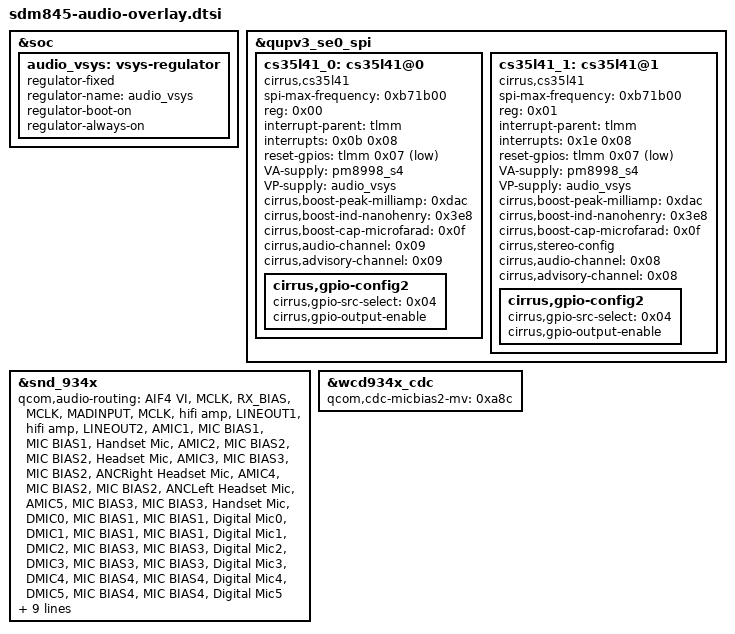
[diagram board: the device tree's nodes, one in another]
/*
 * Copyright (C) 2023 transaero21 <transaero21@elseboot.ru>
 *
 * SPDX-License-Identifier: GPL-2.0
 */

#include "../sdm845-audio-overlay.dtsi"

&soc {
	audio_vsys: vsys-regulator {
		compatible = "regulator-fixed";
		regulator-name = "audio_vsys";
		regulator-boot-on;
		regulator-always-on;
	};
};

&qupv3_se0_spi {
	cs35l41_0: cs35l41@0 {
		#sound-dai-cells = <0x01>;
		compatible = "cirrus,cs35l41";
		spi-max-frequency = <0xb71b00>;
		reg = <0x00>;
		interrupt-parent = <&tlmm>;
		interrupts = <0x0b 0x08>;
		reset-gpios = <&tlmm 0x07 0x01>;
		VA-supply = <&pm8998_s4>;
		VP-supply = <&audio_vsys>;
		cirrus,boost-peak-milliamp = <0xdac>;
		cirrus,boost-ind-nanohenry = <0x3e8>;
		cirrus,boost-cap-microfarad = <0x0f>;
		cirrus,audio-channel = <0x09>;
		cirrus,advisory-channel = <0x09>;

		cirrus,gpio-config2 {
			cirrus,gpio-src-select = <0x04>;
			cirrus,gpio-output-enable;
		};
	};
};

&qupv3_se0_spi {
	cs35l41_1: cs35l41@1 {
		#sound-dai-cells = <0x01>;
		compatible = "cirrus,cs35l41";
		spi-max-frequency = <0xb71b00>;
		reg = <0x01>;
		interrupt-parent = <&tlmm>;
		interrupts = <0x1e 0x08>;
		reset-gpios = <&tlmm 0x07 0x01>;
		VA-supply = <&pm8998_s4>;
		VP-supply = <&audio_vsys>;
		cirrus,boost-peak-milliamp = <0xdac>;
		cirrus,boost-ind-nanohenry = <0x3e8>;
		cirrus,boost-cap-microfarad = <0x0f>;
		cirrus,stereo-config;
		cirrus,audio-channel = <0x08>;
		cirrus,advisory-channel = <0x08>;

		cirrus,gpio-config2 {
			cirrus,gpio-src-select = <0x04>;
			cirrus,gpio-output-enable;
		};
	};
};

&snd_934x {
	qcom,audio-routing =
		"AIF4 VI", "MCLK",
		"RX_BIAS", "MCLK",
		"MADINPUT", "MCLK",
		"hifi amp", "LINEOUT1",
		"hifi amp", "LINEOUT2",
		"AMIC1", "MIC BIAS1",
		"MIC BIAS1", "Handset Mic",
		"AMIC2", "MIC BIAS2",
		"MIC BIAS2", "Headset Mic",
		"AMIC3", "MIC BIAS3",
		"MIC BIAS2", "ANCRight Headset Mic",
		"AMIC4", "MIC BIAS2",
		"MIC BIAS2", "ANCLeft Headset Mic",
		"AMIC5", "MIC BIAS3",
		"MIC BIAS3", "Handset Mic",
		"DMIC0", "MIC BIAS1",
		"MIC BIAS1", "Digital Mic0",
		"DMIC1", "MIC BIAS1",
		"MIC BIAS1", "Digital Mic1",
		"DMIC2", "MIC BIAS3",
		"MIC BIAS3", "Digital Mic2",
		"DMIC3", "MIC BIAS3",
		"MIC BIAS3", "Digital Mic3",
		"DMIC4", "MIC BIAS4",
		"MIC BIAS4", "Digital Mic4",
		"DMIC5", "MIC BIAS4",
		"MIC BIAS4", "Digital Mic5";

	qcom,msm-mbhc-hs-mic-max-threshold-mv = <0x9f6>;
	qcom,msm-mbhc-hs-mic-min-threshold-mv = <0x4b>;

	/delete-property/ qcom,usbc-analog-en2-gpio;

	qcom,msm-mbhc-usbc-audio-supported;
	pinctrl-names = "aud_active", "aud_sleep",
		"quat-mi2s-sleep", "quat-mi2s-active",
		"quat-mi2s-sleep-b2", "quat-mi2s-active-b2";
	pinctrl-2 = <&quat_mi2s_lines_sleep &quat_mi2s_sd2_sleep>;
	pinctrl-3 = <&quat_mi2s_lines_active &quat_mi2s_sd2_active>;
	pinctrl-4 = <&quat_mi2s_lines_sleep>;
	pinctrl-5 = <&quat_mi2s_lines_active>;
};

&wcd934x_cdc {
	qcom,cdc-micbias2-mv = <0xa8c>;
};
